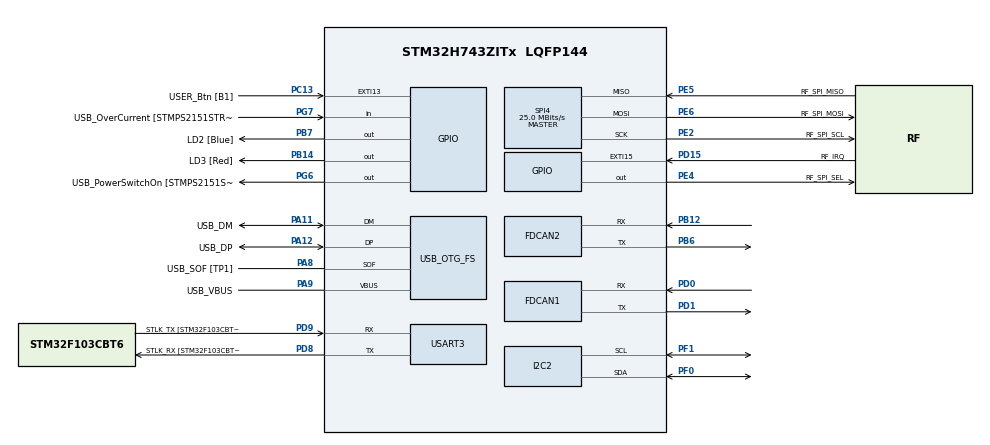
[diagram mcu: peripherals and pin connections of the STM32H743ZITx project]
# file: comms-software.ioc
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ADC3.Channel-0\#ChannelRegularConversion=ADC_CHANNEL_TEMPSENSOR
ADC3.NbrOfConversionFlag=1
ADC3.OffsetNumber-0\#ChannelRegularConversion=ADC_OFFSET_NONE
ADC3.OffsetSignedSaturation-0\#ChannelRegularConversion=DISABLE
ADC3.Rank-0\#ChannelRegularConversion=1
ADC3.SamplingTime-0\#ChannelRegularConversion=ADC_SAMPLETIME_1CYCLE_5
Dma.ADC3.1.Direction=DMA_PERIPH_TO_MEMORY
Dma.ADC3.1.EventEnable=DISABLE
Dma.ADC3.1.FIFOMode=DMA_FIFOMODE_DISABLE
Dma.ADC3.1.Instance=DMA1_Stream0
Dma.ADC3.1.MemDataAlignment=DMA_MDATAALIGN_HALFWORD
Dma.ADC3.1.MemInc=DMA_MINC_ENABLE
Dma.ADC3.1.Mode=DMA_CIRCULAR
Dma.ADC3.1.PeriphDataAlignment=DMA_PDATAALIGN_HALFWORD
Dma.ADC3.1.PeriphInc=DMA_PINC_DISABLE
Dma.ADC3.1.Polarity=HAL_DMAMUX_REQ_GEN_RISING
Dma.ADC3.1.Priority=DMA_PRIORITY_LOW
Dma.ADC3.1.RequestNumber=1
Dma.ADC3.1.SignalID=NONE
Dma.ADC3.1.SyncEnable=DISABLE
Dma.ADC3.1.SyncPolarity=HAL_DMAMUX_SYNC_NO_EVENT
Dma.ADC3.1.SyncRequestNumber=1
Dma.ADC3.1.SyncSignalID=NONE
Dma.Request0=USART3_RX
Dma.Request1=ADC3
Dma.USART3_RX.0.Direction=DMA_PERIPH_TO_MEMORY
Dma.USART3_RX.0.EventEnable=DISABLE
Dma.USART3_RX.0.FIFOMode=DMA_FIFOMODE_DISABLE
Dma.USART3_RX.0.Instance=DMA1_Stream1
Dma.USART3_RX.0.MemDataAlignment=DMA_MDATAALIGN_BYTE
Dma.USART3_RX.0.MemInc=DMA_MINC_ENABLE
Dma.USART3_RX.0.Mode=DMA_NORMAL
Dma.USART3_RX.0.PeriphDataAlignment=DMA_PDATAALIGN_BYTE
Dma.USART3_RX.0.PeriphInc=DMA_PINC_DISABLE
Dma.USART3_RX.0.Polarity=HAL_DMAMUX_REQ_GEN_RISING
Dma.USART3_RX.0.Priority=DMA_PRIORITY_LOW
Dma.USART3_RX.0.RequestNumber=1
Dma.USART3_RX.0.SignalID=NONE
Dma.USART3_RX.0.SyncEnable=DISABLE
Dma.USART3_RX.0.SyncPolarity=HAL_DMAMUX_SYNC_NO_EVENT
Dma.USART3_RX.0.SyncRequestNumber=1
Dma.USART3_RX.0.SyncSignalID=NONE
FDCAN1.CalculateBaudRateNominal=500000
FDCAN1.CalculateTimeBitNominal=2000
FDCAN1.CalculateTimeQuantumNominal=20.0
FDCAN1.DataPrescaler=25
FDCAN1.DataTimeSeg1=2
FDCAN1.FrameFormat=FDCAN_FRAME_FD_NO_BRS
FDCAN1.NominalPrescaler=1
FDCAN1.NominalSyncJumpWidth=13
FDCAN1.NominalTimeSeg1=86
FDCAN1.NominalTimeSeg2=13
FDCAN1.RxFifo0ElmtSize=FDCAN_DATA_BYTES_64
FDCAN1.RxFifo0ElmtsNbr=20
FDCAN1.TxElmtSize=FDCAN_DATA_BYTES_64
FDCAN1.TxFifoQueueElmtsNbr=1
FDCAN2.CalculateBaudRateNominal=500000
FDCAN2.CalculateTimeBitNominal=2000
FDCAN2.CalculateTimeQuantumNominal=20.0
FDCAN2.DataPrescaler=25
FDCAN2.DataTimeSeg1=2
FDCAN2.ExtFiltersNbr=1
FDCAN2.FrameFormat=FDCAN_FRAME_FD_NO_BRS
FDCAN2.MessageRAMOffset=1279
FDCAN2.NominalPrescaler=1
FDCAN2.NominalSyncJumpWidth=13
FDCAN2.NominalTimeSeg1=86
FDCAN2.NominalTimeSeg2=13
FDCAN2.RxFifo1ElmtSize=FDCAN_DATA_BYTES_64
FDCAN2.RxFifo1ElmtsNbr=20
FDCAN2.TxElmtSize=FDCAN_DATA_BYTES_64
FDCAN2.TxFifoQueueElmtsNbr=1
IWDG1.Prescaler=IWDG_PRESCALER_128
Mcu.Family=STM32H7
Mcu.Name=STM32H743ZITx
Mcu.Package=LQFP144
NVIC.DMA1_Stream0_IRQn=true\:0\:0\:false\:false\:true\:false\:true\:true
NVIC.DMA1_Stream1_IRQn=true\:0\:0\:false\:false\:true\:false\:true\:true
NVIC.EXTI15_10_IRQn=true\:5\:0\:true\:true\:false\:1\:true\:true\:true
NVIC.FDCAN1_IT0_IRQn=true\:5\:0\:true\:false\:true\:true\:true\:true
NVIC.FDCAN2_IT1_IRQn=true\:5\:0\:true\:false\:true\:true\:true\:true
NVIC.PriorityGroup=NVIC_PRIORITYGROUP_4
NVIC.TIM6_DAC_IRQn=true\:15\:0\:false\:false\:true\:false\:true\:true
NVIC.TimeBase=TIM6_DAC_IRQn
NVIC.TimeBaseIP=TIM6
NVIC.USART3_IRQn=true\:5\:0\:true\:false\:true\:true\:true\:true
PA1.GPIO_Label=RMII_REF_CLK
PA1.Signal=ETH_REF_CLK
PA10.GPIO_Label=USB_ID
PA10.Signal=USB_OTG_FS_ID
PA11.GPIO_Label=USB_DM
PA11.Mode=Device_Only
PA11.Signal=USB_OTG_FS_DM
PA12.GPIO_Label=USB_DP
PA12.Mode=Device_Only
PA12.Signal=USB_OTG_FS_DP
PA13\ (JTMS/SWDIO).GPIO_Label=TMS
PA13\ (JTMS/SWDIO).Signal=DEBUG_JTMS-SWDIO
PA14\ (JTCK/SWCLK).GPIO_Label=TCK
PA14\ (JTCK/SWCLK).Signal=DEBUG_JTCK-SWCLK
PA2.GPIO_Label=RMII_MDIO
PA2.Signal=ETH_MDIO
PA7.GPIO_Label=RMII_CRS_DV
PA7.Signal=ETH_CRS_DV
PA8.GPIO_Label=USB_SOF [TP1]
PA8.Mode=Activate_SOF_FS
PA8.Signal=USB_OTG_FS_SOF
PA9.GPIO_Label=USB_VBUS
PA9.Mode=Activate_VBUS
PA9.Signal=USB_OTG_FS_VBUS
PB12.Mode=FDCAN_Activate
PB12.Signal=FDCAN2_RX
PB13.GPIO_Label=RMII_TXD1
PB13.Signal=ETH_TXD1
PB14.GPIO_Label=LD3 [Red]
PB14.Signal=GPIO_Output
PB3\ (JTDO/TRACESWO).GPIO_Label=SWO
PB3\ (JTDO/TRACESWO).Signal=DEBUG_JTDO-SWO
PB6.Mode=FDCAN_Activate
PB6.Signal=FDCAN2_TX
PB7.GPIO_Label=LD2 [Blue]
PB7.Signal=GPIO_Output
PC1.GPIO_Label=RMII_MDC
PC1.Signal=ETH_MDC
PC13.GPIO_Label=USER_Btn [B1]
PC13.GPIO_ModeDefaultEXTI=GPIO_MODE_IT_RISING
PC13.GPIO_PuPd=GPIO_NOPULL
PC13.Signal=GPXTI13
PC14-OSC32_IN\ (OSC32_IN).Mode=LSE-External-Oscillator
PC14-OSC32_IN\ (OSC32_IN).Signal=RCC_OSC32_IN
PC15-OSC32_OUT\ (OSC32_OUT).Mode=LSE-External-Oscillator
PC15-OSC32_OUT\ (OSC32_OUT).Signal=RCC_OSC32_OUT
PC4.GPIO_Label=RMII_RXD0
PC4.Signal=ETH_RXD0
PC5.GPIO_Label=RMII_RXD1
PC5.Signal=ETH_RXD1
PD0.Mode=FDCAN_Activate
PD0.Signal=FDCAN1_RX
PD1.Mode=FDCAN_Activate
PD1.Signal=FDCAN1_TX
PD15.GPIO_Label=RF_IRQ
PD15.GPIO_ModeDefaultEXTI=GPIO_MODE_IT_RISING_FALLING
PD15.Signal=GPXTI15
PD8.GPIO_Label=STLK_RX [STM32F103CBT6_PA3]
PD8.Mode=Asynchronous
PD8.Signal=USART3_TX
PD9.GPIO_Label=STLK_TX [STM32F103CBT6_PA2]
PD9.Mode=Asynchronous
PD9.Signal=USART3_RX
PE2.GPIO_Label=RF_SPI_SCL
PE2.Mode=Full_Duplex_Master
PE2.Signal=SPI4_SCK
PE4.GPIO_Label=RF_SPI_SEL
PE4.Signal=GPIO_Output
PE5.GPIO_Label=RF_SPI_MISO
PE5.Mode=Full_Duplex_Master
PE5.Signal=SPI4_MISO
PE6.GPIO_Label=RF_SPI_MOSI
PE6.Mode=Full_Duplex_Master
PE6.Signal=SPI4_MOSI
PF0.Mode=I2C
PF0.Signal=I2C2_SDA
PF1.Mode=I2C
PF1.Signal=I2C2_SCL
PG11.GPIO_Label=RMII_TX_EN
PG11.Signal=ETH_TX_EN
PG13.GPIO_Label=RMII_TXD0
PG13.Signal=ETH_TXD0
PG6.GPIO_Label=USB_PowerSwitchOn [STMPS2151STR_EN]
PG6.Signal=GPIO_Output
PG7.GPIO_Label=USB_OverCurrent [STMPS2151STR_FAULT]
PG7.Signal=GPIO_Input
PH0-OSC_IN\ (PH0).GPIO_Label=MCO
PH0-OSC_IN\ (PH0).Mode=HSE-External-Oscillator
PH0-OSC_IN\ (PH0).Signal=RCC_OSC_IN
PH1-OSC_OUT\ (PH1).Mode=HSE-External-Oscillator
PH1-OSC_OUT\ (PH1).Signal=RCC_OSC_OUT
ProjectManager.HeapSize=0x200
ProjectManager.StackSize=0x400
ProjectManager.TargetToolchain=STM32CubeIDE
RCC.48MHZClocksFreq_Value=24000000
RCC.ADCFreq_Value=75000000
RCC.AHBFreq_Value=216000000
RCC.APB1CLKDivider=RCC_HCLK_DIV4
RCC.APB1Freq_Value=64000000
RCC.APB1TimFreq_Value=108000000
RCC.APB2CLKDivider=RCC_HCLK_DIV2
RCC.APB2Freq_Value=64000000
RCC.APB2TimFreq_Value=216000000
RCC.APB3Freq_Value=64000000
RCC.APB4Freq_Value=64000000
RCC.CortexFreq_Value=64000000
RCC.DIVM1=1
RCC.DIVM2=1
RCC.DIVN1=18
RCC.DIVN2=18
RCC.DIVQ1=3
RCC.DIVQ2=3
RCC.HCLKFreq_Value=64000000
RCC.HSE_VALUE=8000000
RCC.HSI_VALUE=64000000
RCC.PLL2FRACN=6144
RCC.PLL3FRACN=0
RCC.PLLFRACN=6144
RCC.PLLM=25
RCC.PLLMUL=RCC_PLL_MUL9
RCC.PLLN=432
RCC.PLLQ=9
RCC.PRESCALERUSB=RCC_USBCLKSOURCE_PLL_DIV1_5
RCC.PWR_Regulator_Voltage_Scale=PWR_REGULATOR_VOLTAGE_SCALE2
RCC.SPI123CLockSelection=RCC_SPI123CLKSOURCE_CLKP
RCC.SYSCLKFreq_VALUE=64000000
RCC.SYSCLKSourceVirtual=RCC_SYSCLKSOURCE_PLLCLK
RCC.Spi45ClockSelection=RCC_SPI45CLKSOURCE_PLL2
RCC.USBFreq_Value=50000000
RCC.VCOOutputFreq_Value=432000000
SPI4.BaudRatePrescaler=SPI_BAUDRATEPRESCALER_2
SPI4.CalculateBaudRate=25.0 MBits/s
SPI4.DataSize=SPI_DATASIZE_8BIT
SPI4.Direction=SPI_DIRECTION_2LINES
SPI4.Mode=SPI_MODE_MASTER
SPI4.VirtualType=VM_MASTER
USART3.VirtualMode-Asynchronous=VM_ASYNC
USB_OTG_FS.VirtualMode=Device_Only
VP_ADC3_TempSens_Input.Mode=IN-TempSens
VP_ADC3_Vref_Input.Mode=IN-Vrefint
VP_IWDG1_VS_IWDG.Mode=IWDG_Activate
VP_RTC_VS_RTC_Activate.Mode=RTC_Enabled
VP_RTC_VS_RTC_Calendar.Mode=RTC_Calendar
VP_SYS_VS_tim6.Mode=TIM6
board=NUCLEO-H743ZI

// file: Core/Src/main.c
/* USER CODE BEGIN Header */
/**
  ******************************************************************************
  * @file           : main.c
  * @brief          : Main program body
  ******************************************************************************
  * @attention
  *
  * Copyright (c) 2022 STMicroelectronics.
  * All rights reserved.
  *
  * This software is licensed under terms that can be found in the LICENSE file
  * in the root directory of this software component.
  * If no LICENSE file comes with this software, it is provided AS-IS.
  *
  ******************************************************************************
  */
/* USER CODE END Header */
#include "main.h"

/* USER CODE BEGIN Includes */
#include "FreeRTOS.h"
#include "list.h"
#include "task.h"
/* USER CODE END Includes */

ADC_HandleTypeDef hadc3;
DMA_HandleTypeDef hdma_adc3;

FDCAN_HandleTypeDef hfdcan1;
FDCAN_HandleTypeDef hfdcan2;

I2C_HandleTypeDef hi2c2;

IWDG_HandleTypeDef hiwdg1;

RTC_HandleTypeDef hrtc;

SPI_HandleTypeDef hspi4;

UART_HandleTypeDef huart3;
DMA_HandleTypeDef hdma_usart3_rx;

PCD_HandleTypeDef hpcd_USB_OTG_FS;

void SystemClock_Config(void);
void PeriphCommonClock_Config(void);
static void MX_GPIO_Init(void);
static void MX_DMA_Init(void);
static void MX_ADC3_Init(void);
static void MX_I2C2_Init(void);
static void MX_FDCAN1_Init(void);
static void MX_FDCAN2_Init(void);
static void MX_IWDG1_Init(void);
static void MX_USB_OTG_FS_PCD_Init(void);
static void MX_USART3_UART_Init(void);
static void MX_RTC_Init(void);
static void MX_SPI4_Init(void);
static void MX_NVIC_Init(void);
/* USER CODE BEGIN PFP */
void vTask1(void * pvParameters);
void vTask2(void * pvParameters);
/* USER CODE END PFP */

int main(void)
{

  /* MCU Configuration--------------------------------------------------------*/

  /* Reset of all peripherals, Initializes the Flash interface and the Systick. */
  HAL_Init();

  /* Configure the system clock */
  SystemClock_Config();

/* Configure the peripherals common clocks */
  PeriphCommonClock_Config();

  /* Initialize all configured peripherals */
  MX_GPIO_Init();
  MX_DMA_Init();
  MX_ADC3_Init();
  MX_I2C2_Init();
  MX_FDCAN1_Init();
  MX_FDCAN2_Init();
  MX_IWDG1_Init();
  MX_USB_OTG_FS_PCD_Init();
  MX_USART3_UART_Init();
  MX_RTC_Init();
  MX_SPI4_Init();

  /* Initialize interrupts */
  MX_NVIC_Init();
  /* USER CODE BEGIN 2 */

    main_cpp();
  /* USER CODE END 2 */

  /* Infinite loop */
  while (1)
  {

  }
}

void SystemClock_Config(void)
{
  RCC_OscInitTypeDef RCC_OscInitStruct = {0};
  RCC_ClkInitTypeDef RCC_ClkInitStruct = {0};

  /** Supply configuration update enable
  */
  HAL_PWREx_ConfigSupply(PWR_LDO_SUPPLY);

  /** Configure the main internal regulator output voltage
  */
  __HAL_PWR_VOLTAGESCALING_CONFIG(PWR_REGULATOR_VOLTAGE_SCALE2);

  while(!__HAL_PWR_GET_FLAG(PWR_FLAG_VOSRDY)) {}

  /** Initializes the RCC Oscillators according to the specified parameters
  * in the RCC_OscInitTypeDef structure.
  */
  RCC_OscInitStruct.OscillatorType = RCC_OSCILLATORTYPE_HSI|RCC_OSCILLATORTYPE_LSI
                              |RCC_OSCILLATORTYPE_HSE;
  RCC_OscInitStruct.HSEState = RCC_HSE_ON;
  RCC_OscInitStruct.HSIState = RCC_HSI_DIV1;
  RCC_OscInitStruct.HSICalibrationValue = RCC_HSICALIBRATION_DEFAULT;
  RCC_OscInitStruct.LSIState = RCC_LSI_ON;
  RCC_OscInitStruct.PLL.PLLState = RCC_PLL_ON;
  RCC_OscInitStruct.PLL.PLLSource = RCC_PLLSOURCE_HSE;
  RCC_OscInitStruct.PLL.PLLM = 1;
  RCC_OscInitStruct.PLL.PLLN = 18;
  RCC_OscInitStruct.PLL.PLLP = 2;
  RCC_OscInitStruct.PLL.PLLQ = 3;
  RCC_OscInitStruct.PLL.PLLR = 2;
  RCC_OscInitStruct.PLL.PLLRGE = RCC_PLL1VCIRANGE_3;
  RCC_OscInitStruct.PLL.PLLVCOSEL = RCC_PLL1VCOMEDIUM;
  RCC_OscInitStruct.PLL.PLLFRACN = 6144;
  if (HAL_RCC_OscConfig(&RCC_OscInitStruct) != HAL_OK)
  {
    Error_Handler();
  }

  /** Initializes the CPU, AHB and APB buses clocks
  */
  RCC_ClkInitStruct.ClockType = RCC_CLOCKTYPE_HCLK|RCC_CLOCKTYPE_SYSCLK
                              |RCC_CLOCKTYPE_PCLK1|RCC_CLOCKTYPE_PCLK2
                              |RCC_CLOCKTYPE_D3PCLK1|RCC_CLOCKTYPE_D1PCLK1;
  RCC_ClkInitStruct.SYSCLKSource = RCC_SYSCLKSOURCE_HSI;
  RCC_ClkInitStruct.SYSCLKDivider = RCC_SYSCLK_DIV1;
  RCC_ClkInitStruct.AHBCLKDivider = RCC_HCLK_DIV1;
  RCC_ClkInitStruct.APB3CLKDivider = RCC_APB3_DIV1;
  RCC_ClkInitStruct.APB1CLKDivider = RCC_APB1_DIV1;
  RCC_ClkInitStruct.APB2CLKDivider = RCC_APB2_DIV1;
  RCC_ClkInitStruct.APB4CLKDivider = RCC_APB4_DIV1;

  if (HAL_RCC_ClockConfig(&RCC_ClkInitStruct, FLASH_LATENCY_1) != HAL_OK)
  {
    Error_Handler();
  }
}

void PeriphCommonClock_Config(void)
{
  RCC_PeriphCLKInitTypeDef PeriphClkInitStruct = {0};

  /** Initializes the peripherals clock
  */
  PeriphClkInitStruct.PeriphClockSelection = RCC_PERIPHCLK_ADC|RCC_PERIPHCLK_SPI4;
  PeriphClkInitStruct.PLL2.PLL2M = 1;
  PeriphClkInitStruct.PLL2.PLL2N = 18;
  PeriphClkInitStruct.PLL2.PLL2P = 2;
  PeriphClkInitStruct.PLL2.PLL2Q = 3;
  PeriphClkInitStruct.PLL2.PLL2R = 2;
  PeriphClkInitStruct.PLL2.PLL2RGE = RCC_PLL2VCIRANGE_3;
  PeriphClkInitStruct.PLL2.PLL2VCOSEL = RCC_PLL2VCOMEDIUM;
  PeriphClkInitStruct.PLL2.PLL2FRACN = 6144;
  PeriphClkInitStruct.Spi45ClockSelection = RCC_SPI45CLKSOURCE_PLL2;
  PeriphClkInitStruct.AdcClockSelection = RCC_ADCCLKSOURCE_PLL2;
  if (HAL_RCCEx_PeriphCLKConfig(&PeriphClkInitStruct) != HAL_OK)
  {
    Error_Handler();
  }
}

/**
  * @brief NVIC Configuration.
  * @retval None
  */
static void MX_NVIC_Init(void)
{
  /* EXTI15_10_IRQn interrupt configuration */
  HAL_NVIC_SetPriority(EXTI15_10_IRQn, 5, 0);
  HAL_NVIC_EnableIRQ(EXTI15_10_IRQn);
}

static void MX_ADC3_Init(void)
{

  ADC_ChannelConfTypeDef sConfig = {0};

  /** Common config
  */
  hadc3.Instance = ADC3;
  hadc3.Init.Resolution = ADC_RESOLUTION_16B;
  hadc3.Init.ScanConvMode = ADC_SCAN_DISABLE;
  hadc3.Init.EOCSelection = ADC_EOC_SINGLE_CONV;
  hadc3.Init.LowPowerAutoWait = DISABLE;
  hadc3.Init.ContinuousConvMode = DISABLE;
  hadc3.Init.NbrOfConversion = 1;
  hadc3.Init.DiscontinuousConvMode = DISABLE;
  hadc3.Init.ExternalTrigConv = ADC_SOFTWARE_START;
  hadc3.Init.ExternalTrigConvEdge = ADC_EXTERNALTRIGCONVEDGE_NONE;
  hadc3.Init.ConversionDataManagement = ADC_CONVERSIONDATA_DR;
  hadc3.Init.Overrun = ADC_OVR_DATA_PRESERVED;
  hadc3.Init.LeftBitShift = ADC_LEFTBITSHIFT_NONE;
  hadc3.Init.OversamplingMode = DISABLE;
  if (HAL_ADC_Init(&hadc3) != HAL_OK)
  {
    Error_Handler();
  }

  /** Configure Regular Channel
  */
  sConfig.Channel = ADC_CHANNEL_TEMPSENSOR;
  sConfig.Rank = ADC_REGULAR_RANK_1;
  sConfig.SamplingTime = ADC_SAMPLETIME_1CYCLE_5;
  sConfig.SingleDiff = ADC_SINGLE_ENDED;
  sConfig.OffsetNumber = ADC_OFFSET_NONE;
  sConfig.Offset = 0;
  sConfig.OffsetSignedSaturation = DISABLE;
  if (HAL_ADC_ConfigChannel(&hadc3, &sConfig) != HAL_OK)
  {
    Error_Handler();
  }

}

static void MX_FDCAN1_Init(void)
{

  hfdcan1.Instance = FDCAN1;
  hfdcan1.Init.FrameFormat = FDCAN_FRAME_FD_NO_BRS;
  hfdcan1.Init.Mode = FDCAN_MODE_NORMAL;
  hfdcan1.Init.AutoRetransmission = DISABLE;
  hfdcan1.Init.TransmitPause = DISABLE;
  hfdcan1.Init.ProtocolException = DISABLE;
  hfdcan1.Init.NominalPrescaler = 1;
  hfdcan1.Init.NominalSyncJumpWidth = 13;
  hfdcan1.Init.NominalTimeSeg1 = 86;
  hfdcan1.Init.NominalTimeSeg2 = 13;
  hfdcan1.Init.DataPrescaler = 25;
  hfdcan1.Init.DataSyncJumpWidth = 1;
  hfdcan1.Init.DataTimeSeg1 = 2;
  hfdcan1.Init.DataTimeSeg2 = 1;
  hfdcan1.Init.MessageRAMOffset = 0;
  hfdcan1.Init.StdFiltersNbr = 0;
  hfdcan1.Init.ExtFiltersNbr = 0;
  hfdcan1.Init.RxFifo0ElmtsNbr = 20;
  hfdcan1.Init.RxFifo0ElmtSize = FDCAN_DATA_BYTES_64;
  hfdcan1.Init.RxFifo1ElmtsNbr = 0;
  hfdcan1.Init.RxFifo1ElmtSize = FDCAN_DATA_BYTES_8;
  hfdcan1.Init.RxBuffersNbr = 0;
  hfdcan1.Init.RxBufferSize = FDCAN_DATA_BYTES_8;
  hfdcan1.Init.TxEventsNbr = 0;
  hfdcan1.Init.TxBuffersNbr = 0;
  hfdcan1.Init.TxFifoQueueElmtsNbr = 1;
  hfdcan1.Init.TxFifoQueueMode = FDCAN_TX_FIFO_OPERATION;
  hfdcan1.Init.TxElmtSize = FDCAN_DATA_BYTES_64;
  if (HAL_FDCAN_Init(&hfdcan1) != HAL_OK)
  {
    Error_Handler();
  }

}

static void MX_FDCAN2_Init(void)
{

  hfdcan2.Instance = FDCAN2;
  hfdcan2.Init.FrameFormat = FDCAN_FRAME_FD_NO_BRS;
  hfdcan2.Init.Mode = FDCAN_MODE_NORMAL;
  hfdcan2.Init.AutoRetransmission = DISABLE;
  hfdcan2.Init.TransmitPause = DISABLE;
  hfdcan2.Init.ProtocolException = DISABLE;
  hfdcan2.Init.NominalPrescaler = 1;
  hfdcan2.Init.NominalSyncJumpWidth = 13;
  hfdcan2.Init.NominalTimeSeg1 = 86;
  hfdcan2.Init.NominalTimeSeg2 = 13;
  hfdcan2.Init.DataPrescaler = 25;
  hfdcan2.Init.DataSyncJumpWidth = 1;
  hfdcan2.Init.DataTimeSeg1 = 2;
  hfdcan2.Init.DataTimeSeg2 = 1;
  hfdcan2.Init.MessageRAMOffset = 1279;
  hfdcan2.Init.StdFiltersNbr = 0;
  hfdcan2.Init.ExtFiltersNbr = 1;
  hfdcan2.Init.RxFifo0ElmtsNbr = 0;
  hfdcan2.Init.RxFifo0ElmtSize = FDCAN_DATA_BYTES_8;
  hfdcan2.Init.RxFifo1ElmtsNbr = 20;
  hfdcan2.Init.RxFifo1ElmtSize = FDCAN_DATA_BYTES_64;
  hfdcan2.Init.RxBuffersNbr = 0;
  hfdcan2.Init.RxBufferSize = FDCAN_DATA_BYTES_8;
  hfdcan2.Init.TxEventsNbr = 0;
  hfdcan2.Init.TxBuffersNbr = 0;
  hfdcan2.Init.TxFifoQueueElmtsNbr = 1;
  hfdcan2.Init.TxFifoQueueMode = FDCAN_TX_FIFO_OPERATION;
  hfdcan2.Init.TxElmtSize = FDCAN_DATA_BYTES_64;
  if (HAL_FDCAN_Init(&hfdcan2) != HAL_OK)
  {
    Error_Handler();
  }

}

static void MX_I2C2_Init(void)
{

  hi2c2.Instance = I2C2;
  hi2c2.Init.Timing = 0x10707DBC;
  hi2c2.Init.OwnAddress1 = 0;
  hi2c2.Init.AddressingMode = I2C_ADDRESSINGMODE_7BIT;
  hi2c2.Init.DualAddressMode = I2C_DUALADDRESS_DISABLE;
  hi2c2.Init.OwnAddress2 = 0;
  hi2c2.Init.OwnAddress2Masks = I2C_OA2_NOMASK;
  hi2c2.Init.GeneralCallMode = I2C_GENERALCALL_DISABLE;
  hi2c2.Init.NoStretchMode = I2C_NOSTRETCH_DISABLE;
  if (HAL_I2C_Init(&hi2c2) != HAL_OK)
  {
    Error_Handler();
  }

  /** Configure Analogue filter
  */
  if (HAL_I2CEx_ConfigAnalogFilter(&hi2c2, I2C_ANALOGFILTER_ENABLE) != HAL_OK)
  {
    Error_Handler();
  }

  /** Configure Digital filter
  */
  if (HAL_I2CEx_ConfigDigitalFilter(&hi2c2, 0) != HAL_OK)
  {
    Error_Handler();
  }

}

static void MX_IWDG1_Init(void)
{

  hiwdg1.Instance = IWDG1;
  hiwdg1.Init.Prescaler = IWDG_PRESCALER_128;
  hiwdg1.Init.Window = 4095;
  hiwdg1.Init.Reload = 4095;
  if (HAL_IWDG_Init(&hiwdg1) != HAL_OK)
  {
    Error_Handler();
  }

}

static void MX_RTC_Init(void)
{

  RTC_TimeTypeDef sTime = {0};
  RTC_DateTypeDef sDate = {0};

  /** Initialize RTC Only
  */
  hrtc.Instance = RTC;
  hrtc.Init.HourFormat = RTC_HOURFORMAT_24;
  hrtc.Init.AsynchPrediv = 127;
  hrtc.Init.SynchPrediv = 255;
  hrtc.Init.OutPut = RTC_OUTPUT_DISABLE;
  hrtc.Init.OutPutPolarity = RTC_OUTPUT_POLARITY_HIGH;
  hrtc.Init.OutPutType = RTC_OUTPUT_TYPE_OPENDRAIN;
  hrtc.Init.OutPutRemap = RTC_OUTPUT_REMAP_NONE;
  if (HAL_RTC_Init(&hrtc) != HAL_OK)
  {
    Error_Handler();
  }

  /** Initialize RTC and set the Time and Date
  */
  sTime.Hours = 0x0;
  sTime.Minutes = 0x0;
  sTime.Seconds = 0x0;
  sTime.DayLightSaving = RTC_DAYLIGHTSAVING_NONE;
  sTime.StoreOperation = RTC_STOREOPERATION_RESET;
  if (HAL_RTC_SetTime(&hrtc, &sTime, RTC_FORMAT_BCD) != HAL_OK)
  {
    Error_Handler();
  }
  sDate.WeekDay = RTC_WEEKDAY_MONDAY;
  sDate.Month = RTC_MONTH_JANUARY;
  sDate.Date = 0x1;
  sDate.Year = 0x0;

  if (HAL_RTC_SetDate(&hrtc, &sDate, RTC_FORMAT_BCD) != HAL_OK)
  {
    Error_Handler();
  }

}

static void MX_SPI4_Init(void)
{

  /* SPI4 parameter configuration*/
  hspi4.Instance = SPI4;
  hspi4.Init.Mode = SPI_MODE_MASTER;
  hspi4.Init.Direction = SPI_DIRECTION_2LINES;
  hspi4.Init.DataSize = SPI_DATASIZE_8BIT;
  hspi4.Init.CLKPolarity = SPI_POLARITY_LOW;
  hspi4.Init.CLKPhase = SPI_PHASE_1EDGE;
  hspi4.Init.NSS = SPI_NSS_SOFT;
  hspi4.Init.BaudRatePrescaler = SPI_BAUDRATEPRESCALER_2;
  hspi4.Init.FirstBit = SPI_FIRSTBIT_MSB;
  hspi4.Init.TIMode = SPI_TIMODE_DISABLE;
  hspi4.Init.CRCCalculation = SPI_CRCCALCULATION_DISABLE;
  hspi4.Init.CRCPolynomial = 0x0;
  hspi4.Init.NSSPMode = SPI_NSS_PULSE_ENABLE;
  hspi4.Init.NSSPolarity = SPI_NSS_POLARITY_LOW;
  hspi4.Init.FifoThreshold = SPI_FIFO_THRESHOLD_01DATA;
  hspi4.Init.TxCRCInitializationPattern = SPI_CRC_INITIALIZATION_ALL_ZERO_PATTERN;
  hspi4.Init.RxCRCInitializationPattern = SPI_CRC_INITIALIZATION_ALL_ZERO_PATTERN;
  hspi4.Init.MasterSSIdleness = SPI_MASTER_SS_IDLENESS_00CYCLE;
  hspi4.Init.MasterInterDataIdleness = SPI_MASTER_INTERDATA_IDLENESS_00CYCLE;
  hspi4.Init.MasterReceiverAutoSusp = SPI_MASTER_RX_AUTOSUSP_DISABLE;
  hspi4.Init.MasterKeepIOState = SPI_MASTER_KEEP_IO_STATE_DISABLE;
  hspi4.Init.IOSwap = SPI_IO_SWAP_DISABLE;
  if (HAL_SPI_Init(&hspi4) != HAL_OK)
  {
    Error_Handler();
  }

}

static void MX_USART3_UART_Init(void)
{

  huart3.Instance = USART3;
  huart3.Init.BaudRate = 115200;
  huart3.Init.WordLength = UART_WORDLENGTH_8B;
  huart3.Init.StopBits = UART_STOPBITS_1;
  huart3.Init.Parity = UART_PARITY_NONE;
  huart3.Init.Mode = UART_MODE_TX_RX;
  huart3.Init.HwFlowCtl = UART_HWCONTROL_NONE;
  huart3.Init.OverSampling = UART_OVERSAMPLING_16;
  huart3.Init.OneBitSampling = UART_ONE_BIT_SAMPLE_DISABLE;
  huart3.Init.ClockPrescaler = UART_PRESCALER_DIV1;
  huart3.AdvancedInit.AdvFeatureInit = UART_ADVFEATURE_NO_INIT;
  if (HAL_UART_Init(&huart3) != HAL_OK)
  {
    Error_Handler();
  }
  if (HAL_UARTEx_SetTxFifoThreshold(&huart3, UART_TXFIFO_THRESHOLD_1_8) != HAL_OK)
  {
    Error_Handler();
  }
  if (HAL_UARTEx_SetRxFifoThreshold(&huart3, UART_RXFIFO_THRESHOLD_1_8) != HAL_OK)
  {
    Error_Handler();
  }
  if (HAL_UARTEx_DisableFifoMode(&huart3) != HAL_OK)
  {
    Error_Handler();
  }

}

static void MX_USB_OTG_FS_PCD_Init(void)
{

  hpcd_USB_OTG_FS.Instance = USB_OTG_FS;
  hpcd_USB_OTG_FS.Init.dev_endpoints = 9;
  hpcd_USB_OTG_FS.Init.speed = PCD_SPEED_FULL;
  hpcd_USB_OTG_FS.Init.dma_enable = DISABLE;
  hpcd_USB_OTG_FS.Init.phy_itface = PCD_PHY_EMBEDDED;
  hpcd_USB_OTG_FS.Init.Sof_enable = ENABLE;
  hpcd_USB_OTG_FS.Init.low_power_enable = DISABLE;
  hpcd_USB_OTG_FS.Init.lpm_enable = DISABLE;
  hpcd_USB_OTG_FS.Init.battery_charging_enable = ENABLE;
  hpcd_USB_OTG_FS.Init.vbus_sensing_enable = ENABLE;
  hpcd_USB_OTG_FS.Init.use_dedicated_ep1 = DISABLE;
  if (HAL_PCD_Init(&hpcd_USB_OTG_FS) != HAL_OK)
  {
    Error_Handler();
  }

}

static void MX_DMA_Init(void)
{

  /* DMA controller clock enable */
  __HAL_RCC_DMA1_CLK_ENABLE();

  /* DMA interrupt init */
  /* DMA1_Stream0_IRQn interrupt configuration */
  HAL_NVIC_SetPriority(DMA1_Stream0_IRQn, 0, 0);
  HAL_NVIC_EnableIRQ(DMA1_Stream0_IRQn);
  /* DMA1_Stream1_IRQn interrupt configuration */
  HAL_NVIC_SetPriority(DMA1_Stream1_IRQn, 0, 0);
  HAL_NVIC_EnableIRQ(DMA1_Stream1_IRQn);

}

static void MX_GPIO_Init(void)
{
  GPIO_InitTypeDef GPIO_InitStruct = {0};

  /* GPIO Ports Clock Enable */
  __HAL_RCC_GPIOE_CLK_ENABLE();
  __HAL_RCC_GPIOC_CLK_ENABLE();
  __HAL_RCC_GPIOF_CLK_ENABLE();
  __HAL_RCC_GPIOH_CLK_ENABLE();
  __HAL_RCC_GPIOA_CLK_ENABLE();
  __HAL_RCC_GPIOB_CLK_ENABLE();
  __HAL_RCC_GPIOD_CLK_ENABLE();
  __HAL_RCC_GPIOG_CLK_ENABLE();

  /*Configure GPIO pin Output Level */
  HAL_GPIO_WritePin(RF_SPI_SEL_GPIO_Port, RF_SPI_SEL_Pin, GPIO_PIN_RESET);

  /*Configure GPIO pin Output Level */
  HAL_GPIO_WritePin(GPIOB, LD3_Pin|LD2_Pin, GPIO_PIN_RESET);

  /*Configure GPIO pin Output Level */
  HAL_GPIO_WritePin(USB_PowerSwitchOn_GPIO_Port, USB_PowerSwitchOn_Pin, GPIO_PIN_RESET);

  /*Configure GPIO pin : RF_SPI_SEL_Pin */
  GPIO_InitStruct.Pin = RF_SPI_SEL_Pin;
  GPIO_InitStruct.Mode = GPIO_MODE_OUTPUT_PP;
  GPIO_InitStruct.Pull = GPIO_NOPULL;
  GPIO_InitStruct.Speed = GPIO_SPEED_FREQ_LOW;
  HAL_GPIO_Init(RF_SPI_SEL_GPIO_Port, &GPIO_InitStruct);

  /*Configure GPIO pin : USER_Btn_Pin */
  GPIO_InitStruct.Pin = USER_Btn_Pin;
  GPIO_InitStruct.Mode = GPIO_MODE_IT_RISING;
  GPIO_InitStruct.Pull = GPIO_NOPULL;
  HAL_GPIO_Init(USER_Btn_GPIO_Port, &GPIO_InitStruct);

  /*Configure GPIO pins : RMII_MDC_Pin RMII_RXD0_Pin RMII_RXD1_Pin */
  GPIO_InitStruct.Pin = RMII_MDC_Pin|RMII_RXD0_Pin|RMII_RXD1_Pin;
  GPIO_InitStruct.Mode = GPIO_MODE_AF_PP;
  GPIO_InitStruct.Pull = GPIO_NOPULL;
  GPIO_InitStruct.Speed = GPIO_SPEED_FREQ_LOW;
  GPIO_InitStruct.Alternate = GPIO_AF11_ETH;
  HAL_GPIO_Init(GPIOC, &GPIO_InitStruct);

  /*Configure GPIO pins : RMII_REF_CLK_Pin RMII_MDIO_Pin RMII_CRS_DV_Pin */
  GPIO_InitStruct.Pin = RMII_REF_CLK_Pin|RMII_MDIO_Pin|RMII_CRS_DV_Pin;
  GPIO_InitStruct.Mode = GPIO_MODE_AF_PP;
  GPIO_InitStruct.Pull = GPIO_NOPULL;
  GPIO_InitStruct.Speed = GPIO_SPEED_FREQ_LOW;
  GPIO_InitStruct.Alternate = GPIO_AF11_ETH;
  HAL_GPIO_Init(GPIOA, &GPIO_InitStruct);

  /*Configure GPIO pin : RMII_TXD1_Pin */
  GPIO_InitStruct.Pin = RMII_TXD1_Pin;
  GPIO_InitStruct.Mode = GPIO_MODE_AF_PP;
  GPIO_InitStruct.Pull = GPIO_NOPULL;
  GPIO_InitStruct.Speed = GPIO_SPEED_FREQ_LOW;
  GPIO_InitStruct.Alternate = GPIO_AF11_ETH;
  HAL_GPIO_Init(RMII_TXD1_GPIO_Port, &GPIO_InitStruct);

  /*Configure GPIO pins : LD3_Pin LD2_Pin */
  GPIO_InitStruct.Pin = LD3_Pin|LD2_Pin;
  GPIO_InitStruct.Mode = GPIO_MODE_OUTPUT_PP;
  GPIO_InitStruct.Pull = GPIO_NOPULL;
  GPIO_InitStruct.Speed = GPIO_SPEED_FREQ_LOW;
  HAL_GPIO_Init(GPIOB, &GPIO_InitStruct);

  /*Configure GPIO pin : RF_IRQ_Pin */
  GPIO_InitStruct.Pin = RF_IRQ_Pin;
  GPIO_InitStruct.Mode = GPIO_MODE_IT_RISING_FALLING;
  GPIO_InitStruct.Pull = GPIO_NOPULL;
  HAL_GPIO_Init(RF_IRQ_GPIO_Port, &GPIO_InitStruct);

  /*Configure GPIO pin : USB_PowerSwitchOn_Pin */
  GPIO_InitStruct.Pin = USB_PowerSwitchOn_Pin;
  GPIO_InitStruct.Mode = GPIO_MODE_OUTPUT_PP;
  GPIO_InitStruct.Pull = GPIO_NOPULL;
  GPIO_InitStruct.Speed = GPIO_SPEED_FREQ_LOW;
  HAL_GPIO_Init(USB_PowerSwitchOn_GPIO_Port, &GPIO_InitStruct);

  /*Configure GPIO pin : USB_OverCurrent_Pin */
  GPIO_InitStruct.Pin = USB_OverCurrent_Pin;
  GPIO_InitStruct.Mode = GPIO_MODE_INPUT;
  GPIO_InitStruct.Pull = GPIO_NOPULL;
  HAL_GPIO_Init(USB_OverCurrent_GPIO_Port, &GPIO_InitStruct);

  /*Configure GPIO pins : RMII_TX_EN_Pin RMII_TXD0_Pin */
  GPIO_InitStruct.Pin = RMII_TX_EN_Pin|RMII_TXD0_Pin;
  GPIO_InitStruct.Mode = GPIO_MODE_AF_PP;
  GPIO_InitStruct.Pull = GPIO_NOPULL;
  GPIO_InitStruct.Speed = GPIO_SPEED_FREQ_LOW;
  GPIO_InitStruct.Alternate = GPIO_AF11_ETH;
  HAL_GPIO_Init(GPIOG, &GPIO_InitStruct);

}

void HAL_TIM_PeriodElapsedCallback(TIM_HandleTypeDef *htim)
{
  if (htim->Instance == TIM6) {
    HAL_IncTick();
  }
}

void Error_Handler(void)
{
  __disable_irq();
  while (1)
  {
  }
}
